# EFR32FG22C121F512GM40 register map
Vendor: Silicon Labs; Series: EFR32; File version: C
Registers are 32-bit, read-write, reset 0x0 unless marked. A register's access mark holds for its fields unless they carry their own. Offsets are from the block's base; [hi:lo] are bit positions; {n}, {i} and the like mark numbered series; 'fields as' and 'values as' point back to an identical list.

## AGC_S — AGC_S Registers
Base 0xA800C000
Same registers: AGC_NS 0xB800C000
0x00 IPVERSION ro reset 0x1
0x04 EN
  [0] EN — Enable peripheral clock to this module
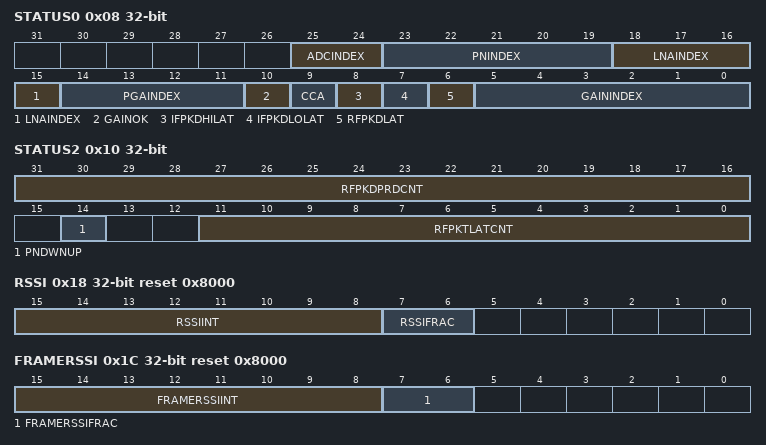
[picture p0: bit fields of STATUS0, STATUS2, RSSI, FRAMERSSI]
0x08 STATUS0 ro
  [25:24] ADCINDEX — ADC Attenuator INDEX
  [23:19] PNINDEX — PN GAIN INDEX
  [18:15] LNAINDEX — LNA GAIN INDEX
  [14:11] PGAINDEX — PGA GAIN INDEX
  [10] GAINOK
  [9] CCA — Clear Channel Assessment
  [8] IFPKDHILAT — IFPKD Hi threshold pass Latch
  [7] IFPKDLOLAT — IFPKD Lo threshold pass Latch
  [6] RFPKDLAT — RFPKD Latch
  [5:0] GAININDEX — Gain Table Index
0x10 STATUS2 ro
  [31:16] RFPKDPRDCNT — RF PKD PERIOD CNT
  [14] PNDWNUP — Allow PN GAIN UP
  [11:0] RFPKTLATCNT — RF PKD Latch CNT
0x18 RSSI ro reset 0x8000
  [15:8] RSSIINT — RSSI integer part
  [7:6] RSSIFRAC — RSSI fractional part
0x1C FRAMERSSI ro reset 0x8000
  [15:8] FRAMERSSIINT — FRAMERSSI integer part
  [7:6] FRAMERSSIFRAC — FRAMERSSI fractional part
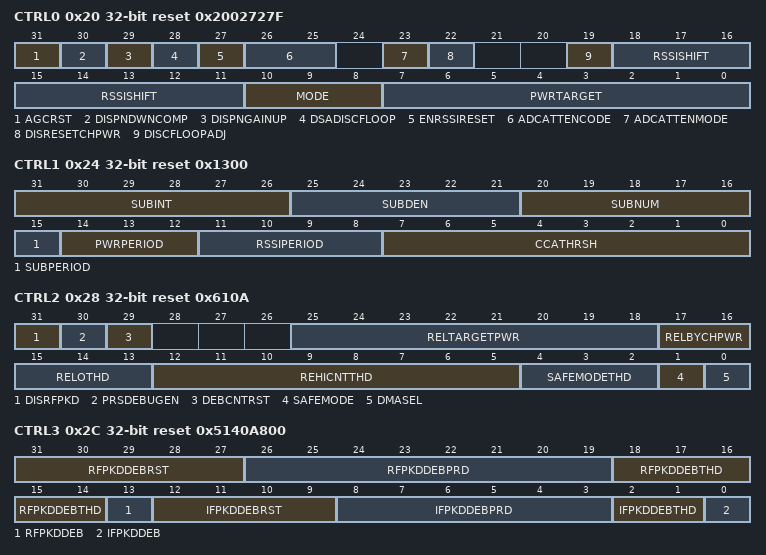
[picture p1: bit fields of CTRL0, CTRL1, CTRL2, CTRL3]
0x20 CTRL0 reset 0x2002727F
  [31] AGCRST — AGC reset
  [30] DISPNDWNCOMP — Disable PN gain decrease compensation
  [29] DISPNGAINUP — Disable PN gain increase
  [28] DSADISCFLOOP — Disable channel filter loop
  [27] ENRSSIRESET — Enables reset of RSSI and CCA
  [26:25] ADCATTENCODE — ADC Attenuator code
  [23] ADCATTENMODE — ADC Attenuator mode
    0=DISABLE (ADC attenuator back-off will not be done by AGC); 1=NOTMAXGAIN (ADC attenuator is backed-off if rxgain is NOT MAXGAIN)
  [22] DISRESETCHPWR — Disable Reset of CHPWR
  [19] DISCFLOOPADJ — Disable gain adjustment by CFLOOP
  [18:11] RSSISHIFT
  [10:8] MODE
    0=CONT (AGC loop is adjusting gain continuously.); 1=LOCKPREDET (Gain is locked once a preamble is detected.); 2=LOCKFRAMEDET (Gain is locked once a sync word is detected.); 3=LOCKDSA (Gain is locked once DSA is detected.)
  [7:0] PWRTARGET — Power Target
0x24 CTRL1 reset 0x1300
  [31:26] SUBINT — Subperiod integer
  [25:21] SUBDEN — Subperiod denominator
  [20:16] SUBNUM — Subperiod numerator
  [15] SUBPERIOD
  [14:12] PWRPERIOD — AGC measure period
  [11:8] RSSIPERIOD — RSSI measure period
  [7:0] CCATHRSH — Clear Channel Assessment (CCA) Threshold
0x28 CTRL2 reset 0x610A
  [31] DISRFPKD — Disable RF PEAKDET
  [30] PRSDEBUGEN — PRS Debug Enable
  [29] DEBCNTRST — Debonce CNT Reset MODE
  [25:18] RELTARGETPWR — Safe Mode Release Power Target
  [17:16] RELBYCHPWR — Safe mode release mode
    0=LO_CNT (Increment counter if IFPKD_LO_LAT signal is not set.); 1=PWR (Increment counter if channel power is below RELTARGETPWR.); 2=LO_CNT_PWR (Increment if either LO_CNT or PWR.); 3=LO_CNT_AND_PWR (Increment if both LO_CNT and PWR.)
  [15:13] RELOTHD — Exit threshold based on Release Counter
  [12:5] REHICNTTHD — Exit threshold based on HICNT
  [4:2] SAFEMODETHD — Enter threshold
  [1] SAFEMODE — AGC safe mode
  [0] DMASEL — DMA select
    0=RSSI; 1=GAIN
0x2C CTRL3 reset 0x5140A800
  [31:27] RFPKDDEBRST — RFPKD_LAT debounce reset delay
  [26:19] RFPKDDEBPRD — RF PEAKDET debance period
  [18:14] RFPKDDEBTHD — RF PEAKDET debance thrshold
  [13] RFPKDDEB — RF PEAKDET debounce mode enable
  [12:9] IFPKDDEBRST — IF PEAKDET debounce period
  [8:3] IFPKDDEBPRD — IF PEAKDET debance period
  [2:1] IFPKDDEBTHD — IF PEAKDET debance thrshold
  [0] IFPKDDEB — IF PEAKDET debounce mode enable
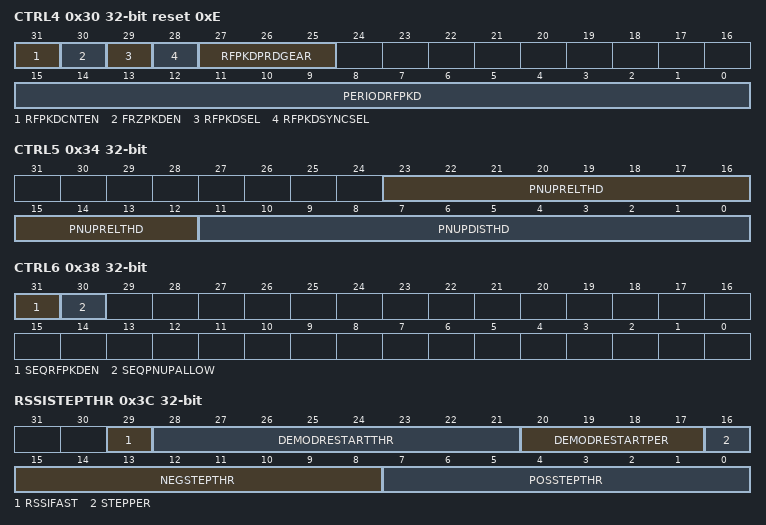
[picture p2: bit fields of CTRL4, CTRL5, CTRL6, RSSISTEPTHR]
0x30 CTRL4 reset 0xE
  [31] RFPKDCNTEN — Counter-based RFPKD Enable
  [30] FRZPKDEN — PKD Freeze Enable
  [29] RFPKDSEL — RF PKD OUTPUT SELECT
  [28] RFPKDSYNCSEL — SYNC RF PKD OUTPUT SELECT
  [27:25] RFPKDPRDGEAR — RFPKD Period Gear
  [15:0] PERIODRFPKD — RFPKD trigger measure period
0x34 CTRL5
  [23:12] PNUPRELTHD — Enable PN GAIN increase THD
  [11:0] PNUPDISTHD — Disable PN GAIN increase THD
0x38 CTRL6
  [31] SEQRFPKDEN — SEQ-based RFPKD Enable
  [30] SEQPNUPALLOW — SEQ Set PN GAIN UP ALLOW
0x3C RSSISTEPTHR
  [29] RSSIFAST — RSSI fast startup
  [28:21] DEMODRESTARTTHR — Demodulator Restart Threshold
  [20:17] DEMODRESTARTPER — Demodulator Restart Period
  [16] STEPPER — Step Period
  [15:8] NEGSTEPTHR — Negative Step Threshold
  [7:0] POSSTEPTHR — Positive Step Threshold
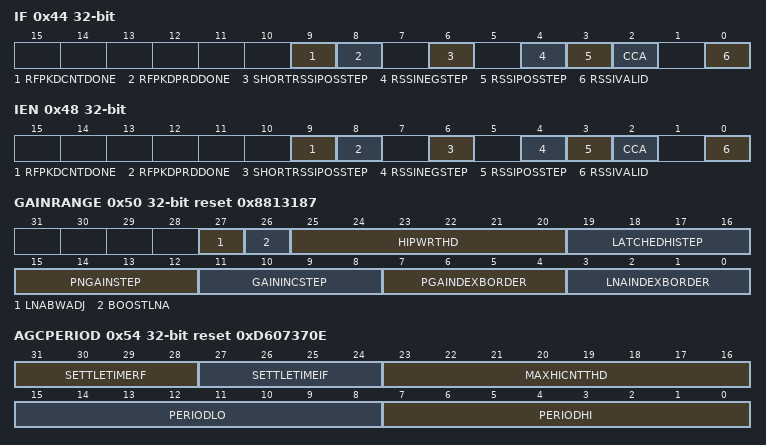
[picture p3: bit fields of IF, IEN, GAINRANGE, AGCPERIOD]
0x44 IF
  [9] RFPKDCNTDONE — RF PKD pulse CNT TOMEOUT
  [8] RFPKDPRDDONE — RF PKD PERIOD CNT TOMEOUT
  [6] SHORTRSSIPOSSTEP — Short-term Positive RSSI Step Detected
  [4] RSSINEGSTEP — Negative RSSI Step Detected
  [3] RSSIPOSSTEP — Positive RSSI Step Detected
  [2] CCA — Clear Channel Assessment
  [0] RSSIVALID — RSSI Value is Valid
0x48 IEN
  [9] RFPKDCNTDONE — RF PKD pulse CNT Interrupt Enable
  [8] RFPKDPRDDONE — RF PKD PERIOD CNT Interrupt Enable
  [6] SHORTRSSIPOSSTEP — SHORTRSSIPOSSTEP Interrupt Enable
  [4] RSSINEGSTEP — RSSINEGSTEP Interrupt Enable
  [3] RSSIPOSSTEP — RSSIPOSSTEP Interrupt Enable
  [2] CCA — CCA Interrupt Enable
  [0] RSSIVALID — RSSIVALID Interrupt Enable
0x50 GAINRANGE reset 0x8813187
  [27] LNABWADJ — LNA BW ADJUST
  [26] BOOSTLNA — LNA GAIN BOOST mode
  [25:20] HIPWRTHD — High power detect thrshold
  [19:16] LATCHEDHISTEP — Ltached Hi step size
  [15:12] PNGAINSTEP — PN Gain Step size
  [11:8] GAININCSTEP — AGC gain increase step size
  [7:4] PGAINDEXBORDER — PGA gain border
  [3:0] LNAINDEXBORDER — LNA gain border
0x54 AGCPERIOD reset 0xD607370E
  [31:28] SETTLETIMERF — RF peak Detector settling time
  [27:24] SETTLETIMEIF — IF peak Detector settling time
  [23:16] MAXHICNTTHD — max hi-countrer threshold
  [15:8] PERIODLO — AGC measure period low
  [7:0] PERIODHI — AGC measure period hi
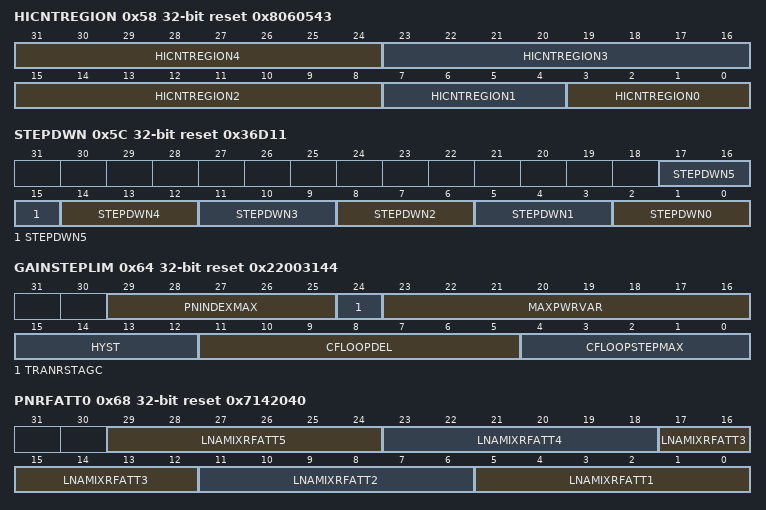
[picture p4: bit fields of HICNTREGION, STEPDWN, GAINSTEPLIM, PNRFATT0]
0x58 HICNTREGION reset 0x8060543
  [31:24] HICNTREGION4 — AGC HICNT to step size map region 4
  [23:16] HICNTREGION3 — AGC HICNT to step size map region 3
  [15:8] HICNTREGION2 — AGC HICNT to step size map region 2
  [7:4] HICNTREGION1 — AGC HICNT to step size map region 1
  [3:0] HICNTREGION0 — AGC HICNT to step size map region 0
0x5C STEPDWN reset 0x36D11
  [3n+2:3n] STEPDWN{n} (n=0..5) — AGC gain step size {n}
0x64 GAINSTEPLIM reset 0x22003144
  [29:25] PNINDEXMAX — MAX PN INDEX
  [24] TRANRSTAGC — power transient detector Reset AGC
  [23:16] MAXPWRVAR — Maximum Power Variation
  [15:12] HYST — Hysteresis
  [11:5] CFLOOPDEL — Channel Filter Loop Delay
  [4:0] CFLOOPSTEPMAX — Maximum step in slow loop
0x68 PNRFATT0 reset 0x7142040
  [6n-1:6n-6] LNAMIXRFATT{n} (n=1..5) — PN RF attenuation code for index {n}
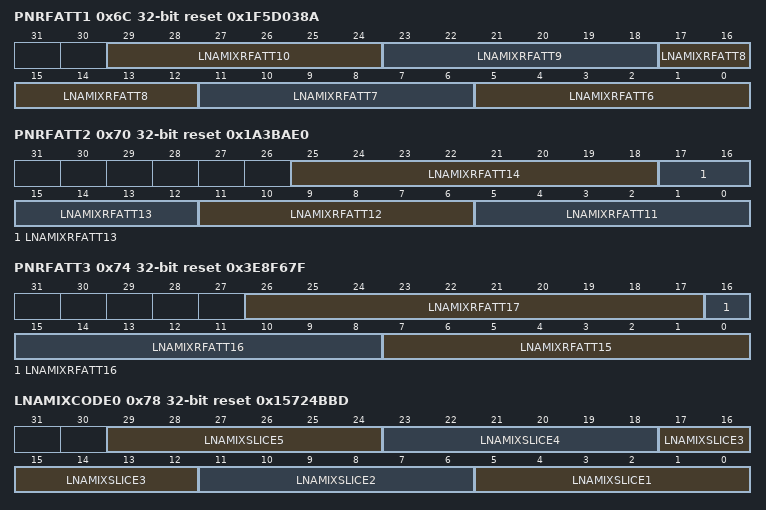
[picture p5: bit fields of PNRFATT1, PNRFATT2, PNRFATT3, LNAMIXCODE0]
0x6C PNRFATT1 reset 0x1F5D038A
  [6n-31:6n-36] LNAMIXRFATT{n} (n=6..10) — PN RF attenuation code for index {n}
0x70 PNRFATT2 reset 0x1A3BAE0
  [25:18] LNAMIXRFATT14 — PN RF attenuation code for index 14
  [17:12] LNAMIXRFATT13 — PN RF attenuation code for index 13
  [11:6] LNAMIXRFATT12 — PN RF attenuation code for index 12
  [5:0] LNAMIXRFATT11 — PN RF attenuation code for index 11
0x74 PNRFATT3 reset 0x3E8F67F
  [26:17] LNAMIXRFATT17 — PN RF attenuation code for index 17
  [16:8] LNAMIXRFATT16 — PN RF attenuation code for index 16
  [7:0] LNAMIXRFATT15 — PN RF attenuation code for index 15
0x78 LNAMIXCODE0 reset 0x15724BBD
  [6n-1:6n-6] LNAMIXSLICE{n} (n=1..5) — LNA/MIX slice code for index {n}
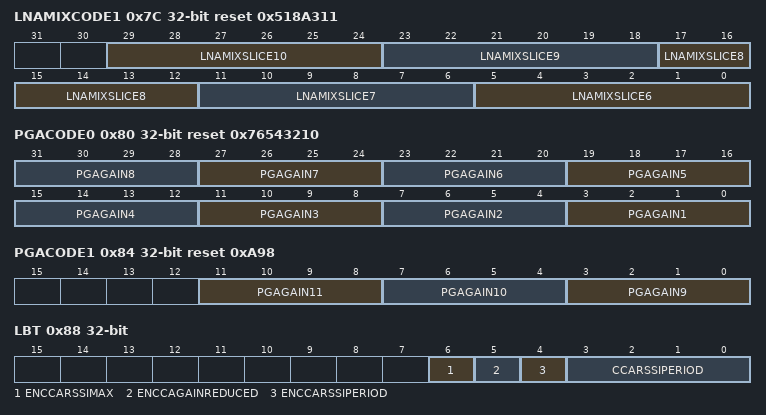
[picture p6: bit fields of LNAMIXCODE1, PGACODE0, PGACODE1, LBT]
0x7C LNAMIXCODE1 reset 0x518A311
  [6n-31:6n-36] LNAMIXSLICE{n} (n=6..10) — LNA/MIX slice code for index {n}
0x80 PGACODE0 reset 0x76543210
  [4n-1:4n-4] PGAGAIN{n} (n=1..8) — PGA GAIN code for index {n}
0x84 PGACODE1 reset 0xA98
  [11:8] PGAGAIN11 — PGA GAIN code for index 11
  [7:4] PGAGAIN10 — PGA GAIN code for index 10
  [3:0] PGAGAIN9 — PGA GAIN code for index 9
0x88 LBT
  [6] ENCCARSSIMAX — Use RSSIMAX to indicate CCA
  [5] ENCCAGAINREDUCED — CCA gain reduced
  [4] ENCCARSSIPERIOD — RSSI PERIOD during CCA measurements
  [3:0] CCARSSIPERIOD — RSSI Period during CCA measurements
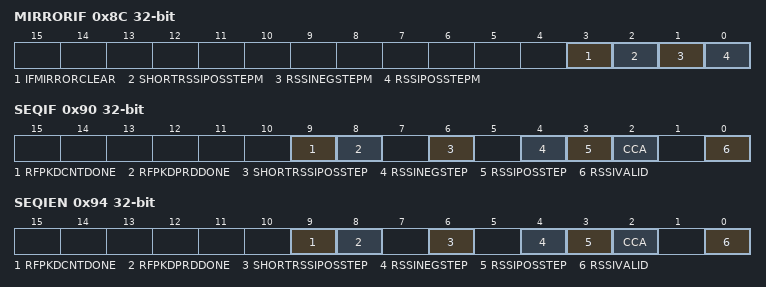
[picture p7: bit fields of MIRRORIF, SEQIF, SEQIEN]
0x8C MIRRORIF
  [3] IFMIRRORCLEAR — Clear bit for the AGC IF MIRROR Register
  [2] SHORTRSSIPOSSTEPM ro — Short-term Positive RSSI Step Detected
  [1] RSSINEGSTEPM ro — Negative RSSI Step Detected
  [0] RSSIPOSSTEPM ro — Positive RSSI Step Detected
0x90 SEQIF
  fields as IF
0x94 SEQIEN
  fields as IEN
